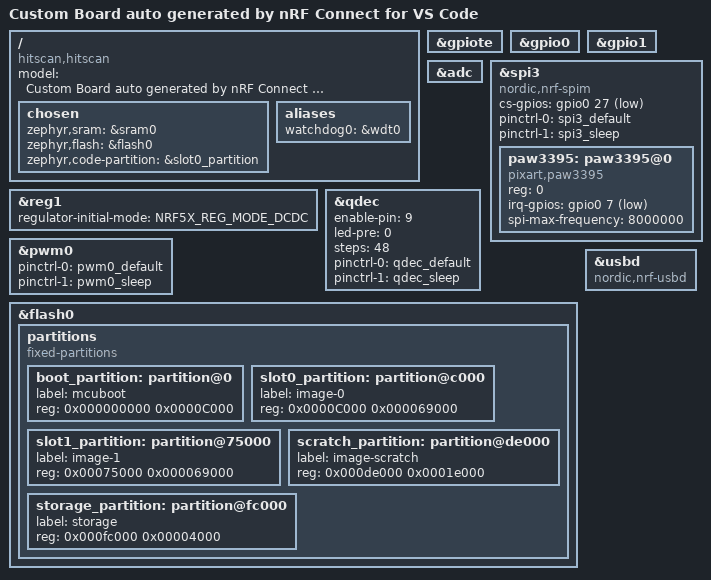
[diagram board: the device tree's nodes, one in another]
/dts-v1/;
#include <nordic/nrf52840_qiaa.dtsi>
#include "hitscan-pinctrl.dtsi"

/ {
	model = "Custom Board auto generated by nRF Connect for VS Code";
	compatible = "hitscan,hitscan";

	chosen {
		zephyr,sram = &sram0;
		zephyr,flash = &flash0;
		zephyr,code-partition = &slot0_partition;
	};
	/* These aliases are provided for compatibility with samples */
	aliases {
		watchdog0 = &wdt0;
	};

	// leds {
	// 	compatible = "gpio-leds";
	// 	led1: led_1 {
	// 		gpios = <&gpio1 8 GPIO_ACTIVE_LOW>;
	// 		label = "LED 1";
	// 	};
	// 	led2: led_2 {
	// 		gpios = <&gpio1 9 GPIO_ACTIVE_LOW>;
	// 		label = "LED 2";
	// 	};
	// 	led3: led_3 {
	// 		gpios = <&gpio0 11 GPIO_ACTIVE_LOW>;
	// 		label = "LED 3";
	// 	};
	// };

};

&gpiote {
	status = "okay";
};

&gpio0 {
	status = "okay";
};

&gpio1 {
	status = "okay";
};

&reg1 {
	regulator-initial-mode = <NRF5X_REG_MODE_DCDC>;
};

&adc {
	status = "okay";
};

&spi3 {
	compatible = "nordic,nrf-spim";
	status = "okay";
	cs-gpios = <&gpio0 27 GPIO_ACTIVE_LOW>;

	pinctrl-0 = <&spi3_default>;
	pinctrl-1 = <&spi3_sleep>;
	pinctrl-names = "default", "sleep";
	// pmw3360@0 {
	// 	compatible = "pixart,pmw3360";
	// 	reg = <0>;
	// 	irq-gpios = <&gpio0 21 (GPIO_ACTIVE_LOW | GPIO_PULL_UP)>;
	// 	spi-max-frequency = <2000000>;
	// };
	paw3395:paw3395@0 {
		compatible = "pixart,paw3395";
		reg = <0>;
		irq-gpios = <&gpio0 7 (GPIO_ACTIVE_LOW | GPIO_PULL_UP)>;
		spi-max-frequency = <8000000>;
	};
};

&qdec {
	status = "okay";
	//For pins P0.0 through P0.31, use the pin number. For example,
    //to use P0.16 for the A pin, set: enable-pin = <16>;

    //For pins P1.0 through P1.31, add 32 to the pin number. For
    //example, to use P1.2 for the A pin, set: enable-pin = <34>;  /* 32 + 2 */
	enable-pin = <9>; // IR_ENC
	led-pre = <0>;
	steps = <48>;
	pinctrl-0 = <&qdec_default>;
	pinctrl-1 = <&qdec_sleep>;
	pinctrl-names = "default", "sleep";
};

&pwm0 {
	status = "okay";
	pinctrl-0 = <&pwm0_default>;
	pinctrl-1 = <&pwm0_sleep>;
	pinctrl-names = "default", "sleep";
};

// &pwm1 {
// 	status = "okay";
// 	pinctrl-0 = <&pwm1_default>;
// 	pinctrl-1 = <&pwm1_sleep>;
// 	pinctrl-names = "default", "sleep";
// };

&flash0 {
	/*
	 * For more information, see:
	 * http://docs.zephyrproject.org/devices/dts/flash_partitions.html
	 */
	partitions {
		compatible = "fixed-partitions";
		#address-cells = <1>;
		#size-cells = <1>;

		boot_partition: partition@0 {
			label = "mcuboot";
			reg = <0x000000000 0x0000C000>;
		};
		slot0_partition: partition@c000 {
			label = "image-0";
			reg = <0x0000C000 0x000069000>;
		};
		slot1_partition: partition@75000 {
			label = "image-1";
			reg = <0x00075000 0x000069000>;
		};
		scratch_partition: partition@de000 {
			label = "image-scratch";
			reg = <0x000de000 0x0001e000>;
		};

		storage_partition: partition@fc000 {
			label = "storage";
			reg = <0x000fc000 0x00004000>;
		};
	};
};

zephyr_udc0: &usbd {
	compatible = "nordic,nrf-usbd";
	status = "okay";
};

/* auto generated 
&flash0 {
	partitions {
		compatible = "fixed-partitions";
		#address-cells = <1>;
		#size-cells = <1>;

		boot_partition: partition@0 {
			label = "mcuboot";
			reg = <0x00000000 DT_SIZE_K(48)>;
		};

		slot0_partition: partition@c000 {
			label = "image-0";
			reg = <0x0000c000 DT_SIZE_K(472)>;
		};

		slot1_partition: partition@82000 {
			label = "image-1";
			reg = <0x00082000 DT_SIZE_K(472)>;
		};

		storage_partition: partition@f8000 {
			label = "storage";
			reg = <0x000f8000 DT_SIZE_K(32)>;
		};
	};
};
*/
